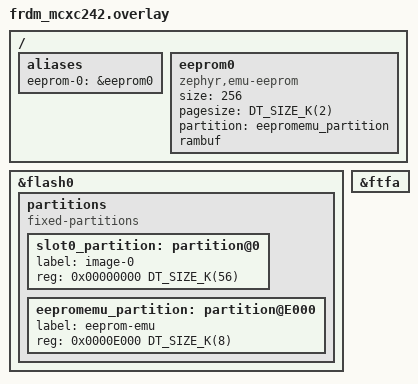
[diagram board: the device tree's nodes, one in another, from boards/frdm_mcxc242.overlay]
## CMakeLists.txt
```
# SPDX-License-Identifier: Apache-2.0

cmake_minimum_required(VERSION 3.28.0)
find_package(Zephyr REQUIRED HINTS $ENV{ZEPHYR_BASE})
project(eeprom)

FILE(GLOB app_sources src/*.c)
target_sources(app PRIVATE ${app_sources})
```

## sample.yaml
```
sample:
  name: EEPROM Sample

tests:
  sample.drivers.eeprom:
    tags: eeprom
    platform_allow:
      - gd32f450i_eval
      - native_sim
      - native_sim/native/64
      - adafruit_qt_py_rp2040/rp2040
      - frdm_mcxn947/mcxn947/cpu0
      - frdm_imxrt1186/mimxrt1186/cm33
      - frdm_imxrt1186/mimxrt1186/cm7
    integration_platforms:
      - native_sim/native/64
    extra_args:
      - platform:adafruit_qt_py_rp2040/rp2040:SHIELD="adafruit_24lc32"
      - platform:frdm_mcxn947/mcxn947/cpu0:SHIELD="mikroe_eeprom_13_click"
    harness: console
    harness_config:
      type: one_line
      regex:
        - "Reset the MCU to see the increasing boot counter."
  sample.drivers.eeprom.shield.x_nucleo_eeprma2:
    tags:
      - eeprom
      - shield
    depends_on:
      - arduino_gpio
      - arduino_i2c
      - arduino_spi
    platform_exclude:
      - ubx_evkannab1/nrf52832
      - sam_v71_xult/samv71q21
      - sam_v71_xult/samv71q21b
      - pan1781_evb
      - pan1782_evb
      - pan1770_evb
      - pan1780_evb
      - mimxrt1010_evk
    extra_args: SHIELD=x_nucleo_eeprma2
    harness: console
    harness_config:
      fixture: fixture_shield_x_nucleo_eeprma2
    integration_platforms:
      - nucleo_f070rb
```

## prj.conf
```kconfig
CONFIG_PRINTK=y
CONFIG_EEPROM=y
```

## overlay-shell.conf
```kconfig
# Ensure EEPROM shell can be compiled
CONFIG_SHELL=y
CONFIG_EEPROM_SHELL=y
```

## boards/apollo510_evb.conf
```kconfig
CONFIG_EEPROM_SIMULATOR=y
```

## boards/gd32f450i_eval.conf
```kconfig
CONFIG_I2C=y
CONFIG_EEPROM_AT24=y
CONFIG_EEPROM_INIT_PRIORITY=75
```

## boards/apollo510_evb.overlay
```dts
/*
 * Copyright (c) 2025 Ambiq Micro Inc. <www.ambiq.com>
 *
 * SPDX-License-Identifier: Apache-2.0
 */

/ {
	aliases {
		eeprom-0 = &sim_eeprom0;
	};

	sim_eeprom0: eeprom-simulator-0 {
		compatible = "zephyr,sim-eeprom";
		size = <DT_SIZE_K(4)>;
	};
};
```

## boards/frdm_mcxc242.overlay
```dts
/ {
	aliases {
		eeprom-0 = &eeprom0;
	};

	eeprom0: eeprom0 {
		status = "okay";
		compatible = "zephyr,emu-eeprom";
		size = <256>;
		pagesize = <DT_SIZE_K(2)>;
		partition = <&eepromemu_partition>;
		rambuf;
	};
};

&flash0 {
	partitions {
		compatible = "fixed-partitions";
		#address-cells = <1>;
		#size-cells = <1>;

		slot0_partition: partition@0 {
			label = "image-0";
			reg = <0x00000000 DT_SIZE_K(56)>;
		};
		eepromemu_partition: partition@E000 {
			label = "eeprom-emu";
			reg = <0x0000E000 DT_SIZE_K(8)>;
		};
	};
};

&ftfa {
	status = "okay";
};
```

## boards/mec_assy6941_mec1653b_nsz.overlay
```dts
/*
 * Copyright (c) 2026 Microchip Technology Inc.
 *
 * SPDX-License-Identifier: Apache-2.0
 */

/* mec_assy6941 EVB with MEC1653B-NSZ daughter card
 * MEC1653B has internal 8KB EEPROM and controller.
 * Internal pins are disabled to reduce leakage.
 */

/ {
	aliases {
		eeprom-0 = &eeprom;
	};
};

&eeprom {
	pinctrl-0 = <&pspi_cs_n_gpio256
		     &pspi_clk_gpio257
		     &pspi_sdi_gpio252
		     &pspi_sdo_gpio251>;
	pinctrl-names = "default";
	status = "okay";
};
```

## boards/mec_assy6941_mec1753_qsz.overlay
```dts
/*
 * Copyright (c) 2026 Microchip Technology Inc.
 *
 * SPDX-License-Identifier: Apache-2.0
 */

/* mec_assy6941 EVB with MEC1753Q-SZ daughter card
 * MEC1753 has internal 8KB EEPROM and controller.
 * Internal pins are disabled to reduce leakage.
 */

/ {
	aliases {
		eeprom-0 = &eeprom;
	};
};

&eeprom {
	pinctrl-0 = <&pspi_cs_n_gpio256
		     &pspi_clk_gpio257
		     &pspi_sdi_gpio252
		     &pspi_sdo_gpio251>;
	pinctrl-names = "default";
	status = "okay";
};
```

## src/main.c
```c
/*
 * Copyright (c) 2021 Thomas Stranger
 *
 * SPDX-License-Identifier: Apache-2.0
 */

#include <zephyr/kernel.h>
#include <zephyr/sys/printk.h>
#include <zephyr/drivers/eeprom.h>
#include <zephyr/device.h>

#define EEPROM_SAMPLE_OFFSET 0
#define EEPROM_SAMPLE_MAGIC  0xEE9703

struct perisistant_values {
	uint32_t magic;
	uint32_t boot_count;
};

/*
 * Get a device structure from a devicetree node with alias eeprom-0
 */
static const struct device *get_eeprom_device(void)
{
	const struct device *const dev = DEVICE_DT_GET(DT_ALIAS(eeprom_0));

	if (!device_is_ready(dev)) {
		printk("\nError: Device \"%s\" is not ready; "
		       "check the driver initialization logs for errors.\n",
		       dev->name);
		return NULL;
	}

	printk("Found EEPROM device \"%s\"\n", dev->name);
	return dev;
}

int main(void)
{
	const struct device *eeprom = get_eeprom_device();
	size_t eeprom_size;
#if CONFIG_DCACHE
	struct perisistant_values values __aligned(CONFIG_DCACHE_LINE_SIZE);
#else
	struct perisistant_values values;
#endif
	int rc;

	if (eeprom == NULL) {
		return 0;
	}

	eeprom_size = eeprom_get_size(eeprom);
	printk("Using eeprom with size of: %zu.\n", eeprom_size);

	rc = eeprom_read(eeprom, EEPROM_SAMPLE_OFFSET, &values, sizeof(values));
	if (rc < 0) {
		printk("Error: Couldn't read eeprom: err: %d.\n", rc);
		return 0;
	}

	if (values.magic != EEPROM_SAMPLE_MAGIC) {
		values.magic = EEPROM_SAMPLE_MAGIC;
		values.boot_count = 0;
	}

	values.boot_count++;
	printk("Device booted %d times.\n", values.boot_count);

	rc = eeprom_write(eeprom, EEPROM_SAMPLE_OFFSET, &values, sizeof(values));
	if (rc < 0) {
		printk("Error: Couldn't write eeprom: err:%d.\n", rc);
		return 0;
	}

	printk("Reset the MCU to see the increasing boot counter.\n\n");
	return 0;
}
```
